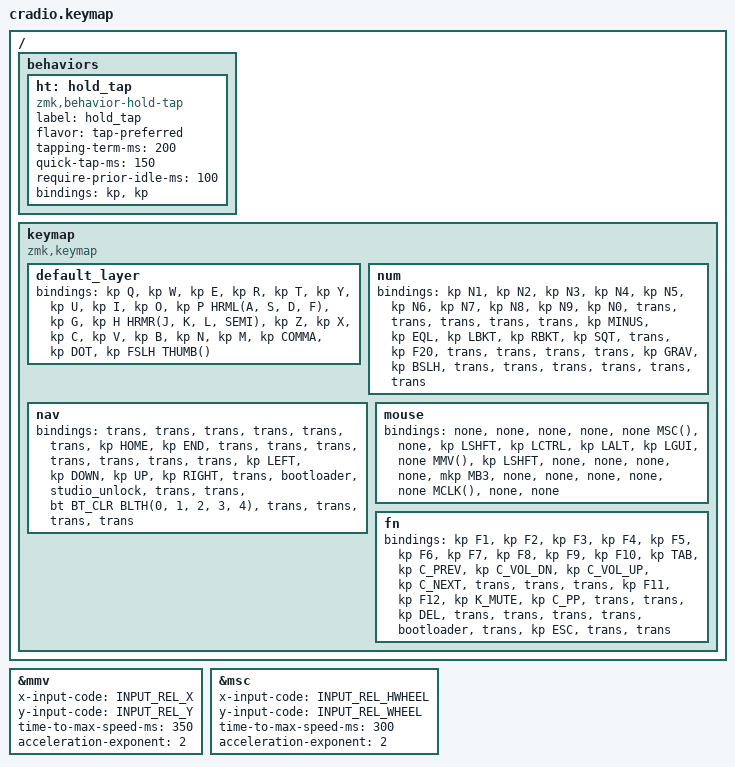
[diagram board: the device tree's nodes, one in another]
// Copyright (c) 2022 The ZMK Contributors
// SPDX-License-Identifier: MIT

#include <behaviors.dtsi>
#include <dt-bindings/zmk/keys.h>
#include <dt-bindings/zmk/bt.h>

#define ZMK_POINTING_DEFAULT_MOVE_VAL 1800
#define ZMK_POINTING_DEFAULT_SCRL_VAL 25
#include <dt-bindings/zmk/pointing.h>

// Home row mods macro
#define HRML(k1,k2,k3,k4) &ht LSHFT k1  &ht LCTRL k2  &ht LALT k3  &ht LGUI k4
#define HRMR(k1,k2,k3,k4) &ht RGUI k1   &ht RALT k2   &ht RCTRL k3 &ht RSHFT k4
#define BLTH(s1,s2,s3,s4,s5) &bt BT_SEL s1 &bt BT_SEL s2 &bt BT_SEL s3 &bt BT_SEL s4 &bt BT_SEL s5


&mmv {
    x-input-code = <INPUT_REL_X>;
    y-input-code = <INPUT_REL_Y>;
    time-to-max-speed-ms = <350>;
    acceleration-exponent = <2>;
};

&msc {
    x-input-code = <INPUT_REL_HWHEEL>;
    y-input-code = <INPUT_REL_WHEEL>;
    time-to-max-speed-ms = <300>;
    acceleration-exponent = <2>;
};

#define MCLK() &mkp LCLK &mkp RCLK
#define MMV() &mmv MOVE_LEFT &mmv MOVE_DOWN &mmv MOVE_UP &mmv MOVE_RIGHT
#define MSC() &msc SCRL_LEFT &msc SCRL_DOWN &msc SCRL_UP &msc SCRL_RIGHT


// num, nav, fn, mouse
#define THUMB() &mo 1 &lt 2 SPACE &lt 3 ENTER &lt 4 BSPC

/ {
    behaviors {
        ht: hold_tap {
            label = "hold_tap";
            compatible = "zmk,behavior-hold-tap";
            #binding-cells = <2>;
            flavor = "tap-preferred";
            tapping-term-ms = <200>;
            quick-tap-ms = <150>;
            require-prior-idle-ms = <100>;
            bindings = <&kp>, <&kp>;
        };
    };

    keymap {
        compatible = "zmk,keymap";
        default_layer {
            bindings = <
        //╭──────────┬──────────┬──────────┬──────────┬──────────╮   ╭──────────┬──────────┬──────────┬──────────┬──────────╮
        //│  Q       │  W       │  E       │  R       │  T       │   │  Y       │  U       │  I       │  O       │  P       │
            &kp Q      &kp W      &kp E      &kp R      &kp T          &kp Y      &kp U      &kp I      &kp O      &kp P
        //├──────────┼──────────┼──────────┼──────────┼──────────┤   ├──────────┼──────────┼──────────┼──────────┼──────────┤
        //│  A       │  S       │  D       │  F       │  G       │   │  H       │  J       │  K       │  L       │ ' "      │
            HRML(A,        S,         D,         F)     &kp G          &kp H      HRMR(J,        K,         L,        SEMI)
        //├──────────┼──────────┼──────────┼──────────┼──────────┤   ├──────────┼──────────┼──────────┼──────────┼──────────┤
        //│  Z       │  X       │  C       │  V       │  B       │   │  N       │  M       │ , <      │ . >      │ / ?      │
            &kp Z      &kp X      &kp C      &kp V      &kp B          &kp N      &kp M      &kp COMMA  &kp DOT    &kp FSLH
        //╰──────────┴──────────┴──────────┼──────────┼──────────┤   ├──────────┼──────────┼──────────┴──────────┴──────────╯
                                                                 THUMB()
        //                                 ╰──────────┴──────────╯   ╰──────────┴──────────╯
            >;
        };

        num {
            bindings = <
        //╭──────────┬──────────┬──────────┬──────────┬──────────╮   ╭──────────┬──────────┬──────────┬──────────┬──────────╮
        //│   1      │  2       │  3       │  4       │ 5        │   │ 6        │ 7        │ 8        │ 9        │  0       │
            &kp N1     &kp N2     &kp N3     &kp N4     &kp N5         &kp N6     &kp N7     &kp N8     &kp N9     &kp N0
        //├──────────┼──────────┼──────────┼──────────┼──────────┤   ├──────────┼──────────┼──────────┼──────────┼──────────┤
        //│          │          │          │          │          │   │ -        │ =        │ [        │ ]        │  '       │
            &trans     &trans     &trans     &trans     &trans         &kp MINUS  &kp EQL    &kp LBKT   &kp RBKT   &kp SQT
        //├──────────┼──────────┼──────────┼──────────┼──────────┤   ├──────────┼──────────┼──────────┼──────────┼──────────┤
        //│          │          │          │          │          │   │          │          │          │          │          │
            &trans     &kp F20    &trans     &trans     &trans         &trans     &kp GRAV   &kp BSLH     &trans     &trans
        //╰──────────┴──────────┴──────────┼──────────┼──────────┤   ├──────────┼──────────┼──────────┴──────────┴──────────╯
                                             &trans     &trans         &trans     &trans
        //                                 ╰──────────┴──────────╯   ╰──────────┴──────────╯
            >;
        };

        nav {
            bindings = <
        //╭──────────┬──────────┬──────────┬──────────┬──────────╮   ╭──────────┬──────────┬──────────┬──────────┬──────────╮
        //│          │          │          │          │          │   │          │          │          │          │          │
            &trans     &trans     &trans     &trans     &trans         &trans     &kp HOME   &kp END    &trans     &trans
        //├──────────┼──────────┼──────────┼──────────┼──────────┤   ├──────────┼──────────┼──────────┼──────────┼──────────┤
        //│          │          │          │          │          │   │          │          │          │          │          │
            &trans     &trans     &trans     &trans     &trans         &kp LEFT   &kp DOWN   &kp UP     &kp RIGHT  &trans
        //├──────────┼──────────┼──────────┼──────────┼──────────┤   ├──────────┼──────────┼──────────┼──────────┼──────────┤
        //│          │          │          │          │          │   │          │          │          │          │          │
          &bootloader &studio_unlock &trans  &trans    &bt BT_CLR      BLTH(0,       1,         2,         3,        4)
        //╰──────────┴──────────┴──────────┼──────────┼──────────┤   ├──────────┼──────────┼──────────┴──────────┴──────────╯
                                             &trans     &trans         &trans     &trans
        //                                 ╰──────────┴──────────╯   ╰──────────┴──────────╯
            >;
        };

        mouse {
            bindings = <
        //╭──────────┬──────────┬──────────┬──────────┬──────────╮   ╭──────────┬──────────┬──────────┬──────────┬──────────╮
        //│          │          │          │          │          │   │          │          │          │          │          │
            &none      &none      &none       &none     &none          MSC()                                       &none
        //├──────────┼──────────┼──────────┼──────────┼──────────┤   ├──────────┼──────────┼──────────┼──────────┼──────────┤
        //│          │          │          │          │          │   │          │          │          │          │          │
           &kp LSHFT  &kp LCTRL  &kp LALT   &kp LGUI      &none          MMV()                                    &kp LSHFT
        //├──────────┼──────────┼──────────┼──────────┼──────────┤   ├──────────┼──────────┼──────────┼──────────┼──────────┤
        //│          │          │          │          │          │   │          │          │          │          │          │
            &none        &none      &none       &none     &mkp MB3       &none      &none      &none      &none      &none
        //╰──────────┴──────────┴──────────┼──────────┼──────────┤   ├──────────┼──────────┼──────────┴──────────┴──────────╯
                                             MCLK()                    &none      &none
        //                                 ╰──────────┴──────────╯   ╰──────────┴──────────╯
            >;
        };

        fn {
            bindings = <
        //╭──────────┬──────────┬──────────┬──────────┬──────────╮   ╭──────────┬──────────┬──────────┬──────────┬──────────╮
        //│          │          │          │          │          │   │          │          │          │          │          │
            &kp F1     &kp F2      &kp F3    &kp F4     &kp F5         &kp F6     &kp F7     &kp F8     &kp F9     &kp F10
        //├──────────┼──────────┼──────────┼──────────┼──────────┤   ├──────────┼──────────┼──────────┼──────────┼──────────┤
        //│          │          │          │          │          │   │          │          │          │          │          │
            &kp TAB   &kp C_PREV &kp C_VOL_DN &kp C_VOL_UP &kp C_NEXT  &trans     &trans     &trans     &kp F11    &kp F12
        //├──────────┼──────────┼──────────┼──────────┼──────────┤   ├──────────┼──────────┼──────────┼──────────┼──────────┤
        //│          │          │          │          │          │   │          │          │          │          │          │
           &kp K_MUTE  &kp C_PP    &trans     &trans    &kp DEL        &trans     &trans     &trans     &trans     &bootloader
        //╰──────────┴──────────┴──────────┼──────────┼──────────┤   ├──────────┼──────────┼──────────┴──────────┴──────────╯
                                             &trans     &kp ESC        &trans     &trans
        //                                 ╰──────────┴──────────╯   ╰──────────┴──────────╯
            >;
        };
    };
};
